# H6 register map
Vendor: Allwinner; Series: H6; File version: 0.1
CPU: CA53 0, little endian, MPU, no FPU, 0 interrupt priority bits
Registers are 32-bit, read-write, reset 0x0 unless marked. A register's access mark holds for its fields unless they carry their own. Offsets are from the block's base; [hi:lo] are bit positions; {n}, {i} and the like mark numbered series; 'fields as' and 'values as' point back to an identical list.

## SMHC0
Base 0x04020000
Same registers: SMHC1 0x04021000
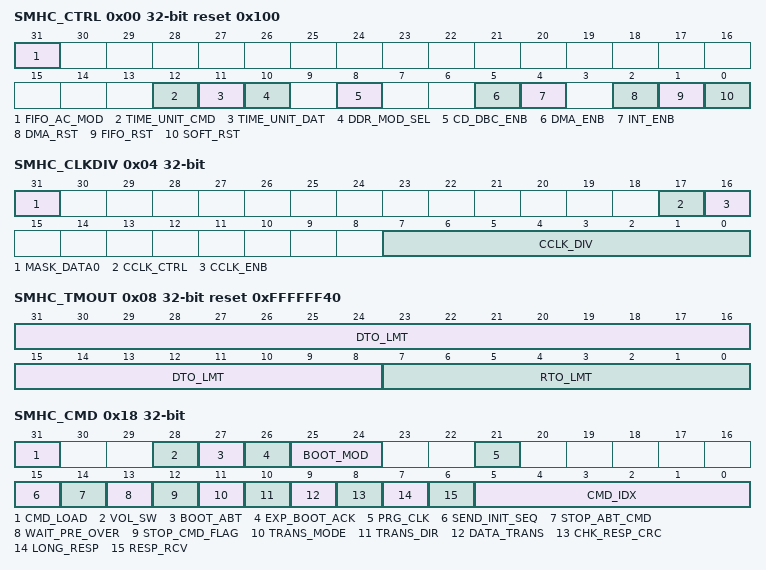
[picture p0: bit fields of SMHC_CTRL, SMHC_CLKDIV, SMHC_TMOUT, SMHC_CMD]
0x00 SMHC_CTRL reset 0x100 — Control Register
  [31] FIFO_AC_MOD — FIFO Access Mode 1: AHB bus 0: DMA bus
    1=AHB (AHB bus); 0=DMA (DMA bus)
  [12] TIME_UNIT_CMD — Time unit for command line Time unit used to calculate command line time out value defined in RTO_LMT. 0: 1 card clock period 1: 256 card clock period
    0=1 card clock period; 1=256 card clock period
  [11] TIME_UNIT_DAT — Time unit for data line Time unit used to calculate data line time out value defined in DTO_LMT. 0: 1 card clock period 1: 256 card clock period
    0=1 card clock period; 1=256 card clock period
  [10] DDR_MOD_SEL — DDR Mode Select Although eMMC`s HS400 speed mode is 8-bit DDR, this filed should be cleared when HS400_MD_EN is set. 0: SDR mode 1: DDR mode
    0=SDR_mode; 1=DDR_mode
  [8] CD_DBC_ENB — Card Detect (Data[3] status) De-bounce Enable 0: Disable de-bounce 1: Enable de-bounce
    0=Disable de-bounce; 1=Enable de-bounce
  [5] DMA_ENB — DMA Global Enable 0: Disable DMA to transfer data, using AHB bus 1: Enable DMA to transfer data
    0=Disable DMA to transfer data, using AHB bus; 1=Enable DMA to transfer data
  [4] INT_ENB — Global Interrupt Enable 0: Disable interrupts 1: Enable interrupts
    0=Disable interrupts; 1=Enable interrupts
  [2] DMA_RST — DMA Reset
  [1] FIFO_RST — FIFO Reset 0: No change 1: Reset FIFO This bit is auto-cleared after completion of reset operation.
    0=No_change; 1=Reset FIFO This bit is auto-cleared after completion of reset operation
  [0] SOFT_RST — Software Reset 0: No change 1: Reset SD/MMC controller This bit is auto-cleared after completion of reset operation.
    0=No_change; 1=Reset SD/MMC controller This bit is auto-cleared after completion of reset operation
0x04 SMHC_CLKDIV — Clock Control Register
  [31] MASK_DATA0 — 0: Do not mask data0 when update clock 1: Mask data0 when update clock
    0=Do not mask data0 when update clock; 1=Mask data0 when update clock
  [17] CCLK_CTRL — Card Clock Output Control 0 : Card clock always on 1 : Turn off card clock when FSM in IDLE state
  [16] CCLK_ENB — Card Clock Enable 0: Card Clock off 1: Card Clock on
    0=Card_Clock_off; 1=Card_Clock_on
  [7:0] CCLK_DIV — Card clock divider n: Source clock is divided by 2*n.(n=0~255) when HS400_MD_EN is set, this field must be cleared.
0x08 SMHC_TMOUT reset 0xFFFFFF40 — Time Out Register
  [31:8] DTO_LMT — Data Timeout Limit
  [7:0] RTO_LMT — Response Timeout Limit
0x0C SMHC_CTYPE — Bus Width Register
  [1:0] CARD_WID — Card Width 00: 1-bit width 01: 4-bit width 1x: 8-bit width
    0=1-bit width; 1=4-bit width; 2=8-bit width
0x10 SMHC_BLKSIZ reset 0x200 — Block Size Register
  [15:0] BLK_SZ — Block Size
0x14 SMHC_BYTCNT reset 0x200 — Byte Count Register
  [31:0] BYTE_CNT — Byte counter Number of bytes to be transferred; should be integer multiple of Block Size for block transfers.
0x18 SMHC_CMD — Command Register
  [31] CMD_LOAD — Start Command. This bit is auto cleared when current command is sent. If there is no any response error happened, a command complete interrupt bit (CMD_OVER) will be set in interrupt register. You should not write any other command before this bit is cleared, or a command busy interrupt bit (CMD_BUSY) will be set in interrupt register.
  [28] VOL_SW — Voltage Switch 0: normal command 1: Voltage switch command, set for CMD11 only
    0=normal command; 1=Voltage switch command, set for CMD11 only
  [27] BOOT_ABT — Boot Abort Setting this bit will terminate the boot operation.
  [26] EXP_BOOT_ACK — Expect Boot Acknowledge. When Software sets this bit along in mandatory boot operation, controller expects a boot acknowledge start pattern of 0-1-0 from the selected card.
  [25:24] BOOT_MOD — Boot Mode 00: Normal command 01: Mandatory Boot operation 10: Alternate Boot operation 11: Reserved
    0=Normal command; 1=Mandatory Boot operation; 2=Alternate Boot operation
  [21] PRG_CLK — Change Clock 0: Normal command 1: Change Card Clock; when this bit is set, controller will change clock domain and clock output. No command will be sent.
    0=Normal command; 1=Change Card Clock; when this bit is set, controller will change clock domain and clock output. No command will be sent.
  [15] SEND_INIT_SEQ — Send Initialization 0: Normal command sending 1: Send initialization sequence before sending this command.
    0=Normal command sending; 1=Send initialization sequence before sending this command
  [14] STOP_ABT_CMD — Stop Abort Command 0: Normal command sending 1: Send Stop or abort command to stop current data transfer in progress.(CMD12, CMD52 for writing `I/O Abort` in SDIO CCCR)
    0=Normal command sending; 1=Send Stop or abort command to stop current data transfer in progress.(CMD12, CMD52 for writing `I/O Abort` in SDIO CCCR)
  [13] WAIT_PRE_OVER — Wait Data Transfer Over 0: Send command at once, do not care of data transferring 1: Wait for data transfer completion before sending current command
    0=Send command at once, do not care of data transferring; 1=Wait for data transfer completion before sending current command
  [12] STOP_CMD_FLAG — Send Stop CMD Automatically (CMD12) 0: Do not send stop command at end of data transfer 1: Send stop command automatically at end of data transfer
    0=Do not send stop command at end of data transfer; 1=Send stop command automatically at end of data transfer
  [11] TRANS_MODE — Transfer Mode 0: Block data transfer command 1: Stream data transfer command
    0=Block data transfer command; 1=Stream data transfer command
  [10] TRANS_DIR — Transfer Direction 0: Read operation 1: Write operation
    0=Read operation; 1=Write operation
  [9] DATA_TRANS — Data Transfer 0: without data transfer 1: with data transfer
    0=without data transfer; 1=with data transfer
  [8] CHK_RESP_CRC — Check Response CRC 0: Do not check response CRC 1: Check response CRC
    0=Do not check response CRC; 1=Check response CRC
  [7] LONG_RESP — Response Type 0:Short Response (48 bits) 1:Long Response (136 bits)
  [6] RESP_RCV — Response Receive 0: Command without Response 1: Command with Response
    0=Command_without_Response; 1=Command_with_Response
  [5:0] CMD_IDX — CMD Index Command index value
0x1C SMHC_CMDARG — Command Argument Register
  [31:0] CMD_ARG — Command argument
0x20 SMHC_RESP0 — Response 0 Register
  [31:0] CMD_RESP0 ro — Response 0 Bit[31:0] of response
0x24 SMHC_RESP1 — Response 1 Register
  [31:0] CMD_RESP1 ro — Response 1 Bit[63:31] of response
0x28 SMHC_RESP2 — Response 2 Register
  [31:0] CMD_RESP2 ro — Response 2 Bit[95:64] of response
0x2C SMHC_RESP3 — Response 3 Register
  [31:0] CMD_RESP3 ro — Response 3 Bit[127:96] of response
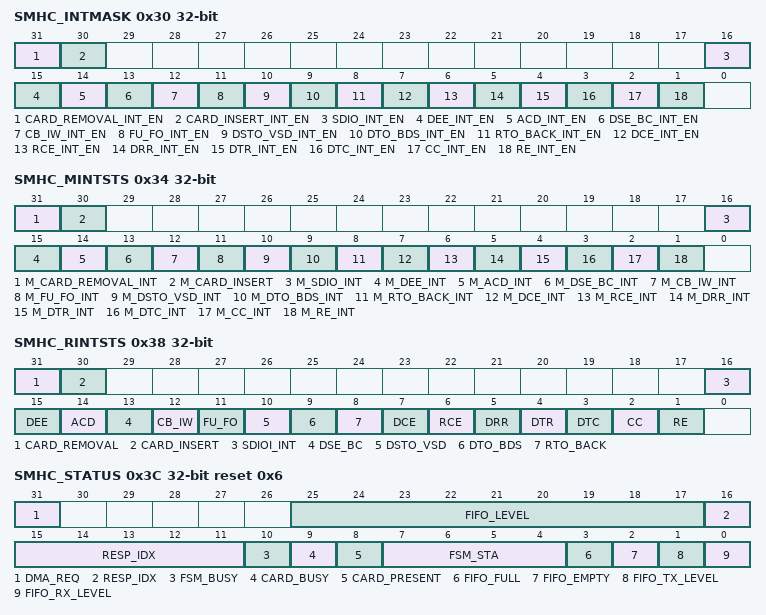
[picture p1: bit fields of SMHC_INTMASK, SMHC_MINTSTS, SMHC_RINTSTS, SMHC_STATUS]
0x30 SMHC_INTMASK — Interrupt Mask Register
  [31] CARD_REMOVAL_INT_EN — Card Removed Interrupt Enable
  [30] CARD_INSERT_INT_EN — Card Inserted Interrupt Enable
  [16] SDIO_INT_EN — SDIO Interrupt Enable
  [15] DEE_INT_EN — Data End-bit Error Interrupt Enable
  [14] ACD_INT_EN — Auto Command Done Interrupt Enable
  [13] DSE_BC_INT_EN — Data Start Error Interrupt Enable
  [12] CB_IW_INT_EN — Command Busy and Illegal Write Interrupt Enable
  [11] FU_FO_INT_EN — FIFO Underrun/Overflow Interrupt Enable
  [10] DSTO_VSD_INT_EN — Data Starvation Timeout/V1.8 Switch Done Interrupt Enable
  [9] DTO_BDS_INT_EN — Data Timeout/Boot Data Start Interrupt Enable
  [8] RTO_BACK_INT_EN — Response Timeout/Boot ACK Received Interrupt Enable
  [7] DCE_INT_EN — Data CRC Error Interrupt Enable
  [6] RCE_INT_EN — Response CRC Error Interrupt Enable
  [5] DRR_INT_EN — Data Receive Request Interrupt Enable
  [4] DTR_INT_EN — Data Transmit Request Interrupt Enable
  [3] DTC_INT_EN — Data Transfer Complete Interrupt Enable
  [2] CC_INT_EN — Command Complete Interrupt Enable
  [1] RE_INT_EN — Response Error Interrupt Enable
0x34 SMHC_MINTSTS — Masked interrupt Status Register
  [31] M_CARD_REMOVAL_INT — Card Removed
  [30] M_CARD_INSERT — Card Inserted
  [16] M_SDIO_INT — SDIO Interrupt
  [15] M_DEE_INT — Data End-bit Error When set during receiving data, it means that host controller does not receive valid data end bit. When set during transmitting data, it means that host controller does not receive CRC status taken or received CRC status taken is negative.
  [14] M_ACD_INT — Auto Command Done When set, it means auto stop command(CMD12) completed.
  [13] M_DSE_BC_INT — Data Start Error When set during receiving data, it means that host controller found a error start bit. When set during transmitting data, it means that busy signal is cleared.
  [12] M_CB_IW_INT — Command Busy and Illegal Write
  [11] M_FU_FO_INT — FIFO Underrun/Overflow
  [10] M_DSTO_VSD_INT — Data Starvation Timeout/V1.8 Switch Done
  [9] M_DTO_BDS_INT — Data Timeout/Boot Data Start
  [8] M_RTO_BACK_INT — Response Timeout/Boot ACK Received
  [7] M_DCE_INT — Data CRC Error When set during receiving data, it means that the received data have data CRC error. When set during transmitting data, it means that the received CRC status taken is negative.
  [6] M_RCE_INT — Response CRC Error
  [5] M_DRR_INT — Data Receive Request When set, it means that there are enough data in FIFO during receiving data.
  [4] M_DTR_INT — Data Transmit Request When set, it means that there are enough space in FIFO during transmitting data.
  [3] M_DTC_INT — Data Transfer Complete
  [2] M_CC_INT — Command Complete
  [1] M_RE_INT — Response Error When set, Transmit Bit error or End Bit error or CMD Index error may occurs.
0x38 SMHC_RINTSTS — Raw Interrupt Status Register
  [31] CARD_REMOVAL write-1-clears — Card Removed This is write-1-to-clear bits.
  [30] CARD_INSERT write-1-clears — Card Inserted This is write-1-to-clear bits.
  [16] SDIOI_INT write-1-clears — SDIO Interrupt This is write-1-to-clear bits.
  [15] DEE write-1-clears — Data End-bit Error When set during receiving data, it means that host controller does not receive valid data end bit. When set during transmitting data, it means that host controller does not receive CRC status taken. This is write-1-to-clear bits.
  [14] ACD write-1-clears — Auto Command Done When set, it means auto stop command(CMD12) completed. This is write-1-to-clear bits.
  [13] DSE_BC write-1-clears — Data Start Error When set during receiving data, it means that host controller found a error start bit. When set during transmitting data, it means that busy signal is cleared. This is write-1-to-clear bits.
  [12] CB_IW write-1-clears — Command Busy and Illegal Write This is write-1-to-clear bits.
  [11] FU_FO write-1-clears — FIFO Underrun/Overflow This is write-1-to-clear bits.
  [10] DSTO_VSD write-1-clears — Data Starvation Timeout/V1.8 Switch Done This is write-1-to-clear bits.
  [9] DTO_BDS write-1-clears — Data Timeout/Boot Data Start This is write-1-to-clear bits.
  [8] RTO_BACK write-1-clears — Response Timeout/Boot ACK Received This is write-1-to-clear bits.
  [7] DCE write-1-clears — Data CRC Error When set during receiving data, it means that the received data have data CRC error. When set during transmitting data, it means that the received CRC status taken is negative. This is write-1-to-clear bits.
  [6] RCE write-1-clears — Response CRC Error This is write-1-to-clear bits.
  [5] DRR write-1-clears — Data Receive Request When set, it means that there are enough data in FIFO during receiving data. This is write-1-to-clear bits.
  [4] DTR write-1-clears — Data Transmit Request When set, it means that there are enough space in FIFO during transmitting data. This is write-1-to-clear bits.
  [3] DTC write-1-clears — Data Transfer Complete This is write-1-to-clear bits.
  [2] CC write-1-clears — Command Complete This is write-1-to-clear bits.
  [1] RE write-1-clears — Response Error When set, Transmit Bit error or End Bit error or CMD Index error may occurs. This is write-1-to-clear bits.
0x3C SMHC_STATUS reset 0x6 — Status Register
  [31] DMA_REQ ro — DMA Request DMA request signal state
  [25:17] FIFO_LEVEL ro — FIFO Level Number of filled locations in FIFO
  [16:11] RESP_IDX ro — Response Index Index of previous response, including any auto-stop sent by controller
  [10] FSM_BUSY ro — Data FSM Busy Data transmit or receive state-machine is busy
  [9] CARD_BUSY ro — Card data busy Inverted version of DATA[0] 0: card data not busy 1: card data busy
    0=card_data_not_busy; 1=card_data_busy
  [8] CARD_PRESENT ro — Data[3] status level of DATA[3], checks whether card is present 0: card not present 1: card present
    0=card_not_present; 1=card_present
  [7:4] FSM_STA ro — Command FSM States 0000: Idle 0001: Send init sequence 0010: TX CMD start bit 0011: TX CMD TX bit 0100: TX CMD index + argument 0101: TX CMD CRC7 0110: TX CMD end bit 0111: RX response start bit 1000: RX response IRQ response 1001: RX response TX bit 1010: RX response CMD index 1011: RX response data 1100: RX response CRC7 1101: RX response end bit 1110: CMD path wait NCC 1111: Wait; CMD-to-response turnaround
  [3] FIFO_FULL ro — FIFO Full 1: FIFO full 0: FIFO not full
    1=FIFO_full; 0=FIFO (FIFO not full)
  [2] FIFO_EMPTY ro — FIFO Empty 1: FIFO Empty 0: FIFO not Empty
    1=FIFO_Empty; 0=FIFO_not_Empty
  [1] FIFO_TX_LEVEL ro — FIFO TX Water Level Flag 0: FIFO didn`t reach transmit trigger level 1: FIFO reached transmit trigger level
    0=FIFO didn`t reach transmit trigger level; 1=FIFO reached transmit trigger level
  [0] FIFO_RX_LEVEL ro — FIFO TX Water Level Flag 0: FIFO didn`t reach receive trigger level 1: FIFO reached receive trigger level
    0=FIFO didn`t reach receive trigger level; 1=FIFO reached receive trigger level
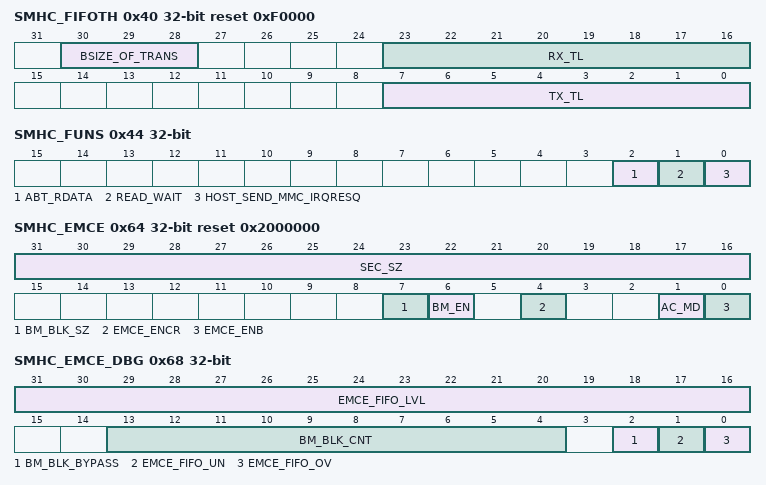
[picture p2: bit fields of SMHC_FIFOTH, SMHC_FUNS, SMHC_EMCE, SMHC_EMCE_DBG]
0x40 SMHC_FIFOTH reset 0xF0000 — FIFO Water Level Register
  [30:28] BSIZE_OF_TRANS — Burst Size of Multiple Transaction 000: 1 transfers 001: 4 010: 8 011: 16 Others: Reserved Should be programmed same as DMA controller multiple transaction size. The units for transfers are the DWORD. A single transfer would be signaled based on this value. Value should be sub-multiple of (RX_TL + 1) and (FIFO_DEPTH - TX_TL) FIFO_DEPTH = 256 FIFO_SIZE = 256 * 32 = 1K Recommended: MSize = 16, TX_TL = 240, RX_TL = 15
    0=1 transfers; 1=_4; 2=_8; 3=16 Others: Reserved Should be programmed same as DMA controller multiple transaction size. The units for transfers are the DWORD. A single transfer would be signaled based on this value. Value should be sub-multiple of (RX_TL + 1) and (FIFO_DEPTH - TX_TL) FIFO_DEPTH = 256 FIFO_SIZE = 256 * 32 = 1K Recommended: MSize = 16, TX_TL = 240, RX_TL = 15
  [23:16] RX_TL — RX Trigger Level 0x0~0xFE: RX Trigger Level is 0~254 0xFF: Reserved FIFO threshold when FIFO request host to receive data from FIFO. When FIFO data level is greater than this value, DMA is request is raised if DMA enabled, or RX interrupt bit is set if interrupt enabled. At the end of packet, if the last transfer is less than this level, the value is ignored and relative request will be raised as usual. Recommended: 15 (means greater than 15)
  [7:0] TX_TL — TX Trigger Level 0x1~0xFF: TX Trigger Level is 1~255 0x0: no trigger FIFO threshold when FIFO requests host to transmit data to FIFO. When FIFO data level is less than or equal to this value, DMA TX request is raised if DMA enabled, or TX request interrupt bit is set if interrupt enabled. At the end of packet, if the last transfer is less than this level, the value is ignored and relative request will be raised as usual. Recommended: 240(means less than or equal to 240)
    0=no trigger FIFO threshold when FIFO requests host to transmit data to FIFO. When FIFO data level is less than or equal to this value, DMA TX request is raised if DMA enabled, or TX request interrupt bit is set if interrupt enabled. At the end of packet, if the last transfer is less than this level, the value is ignored and relative request will be raised as usual. Recommended: 240(means less than or equal to 240)
0x44 SMHC_FUNS — FIFO Function Select Register
  [2] ABT_RDATA — Abort Read Data 0: Ignored 1: After suspend command is issued during read-transfer, software polls card to find when suspend happened. Once suspend occurs, software sets bit to reset data state-machine, which is waiting for next block of data. Used in SDIO card suspends sequence. This bit is auto-cleared once controller reset to idle state.
    0=Ignored; 1=After suspend command is issued during read-transfer, software polls card to find when suspend happened. Once suspend occurs, software sets bit to reset data state-machine, which is waiting for next block of data. Used in SDIO card suspends sequence. This bit is auto-cleared once controller reset to idle state.
  [1] READ_WAIT — Read Wait 0: Clear SDIO read wait 1: Assert SDIO read wait
    0=Clear SDIO read wait; 1=Assert SDIO read wait
  [0] HOST_SEND_MMC_IRQRESQ — Host Send MMC IRQ Response 0: Ignored 1: Send auto IRQ response When host is waiting MMC card interrupt response, setting this bit will make controller cancel wait state and return to idle state, at which time, controller will receive IRQ response sent by itself. This bit is auto-cleared after response is sent.
    0=Ignored; 1=Send auto IRQ response When host is waiting MMC card interrupt response, setting this bit will make controller cancel wait state and return to idle state, at which time, controller will receive IRQ response sent by itself. This bit is auto-cleared after response is sent.
0x48 SMHC_TBC0
  [31:0] TBC0 ro — Transferred Count 0 Number of bytes transferred between card and internal FIFO. The register should be accessed in full to avoid read-coherency problems and read only after data transfer completes.
0x4C SMHC_TBC1
  [31:0] TBC1 ro — Transferred Count 1 Number of bytes transferred between Host/DMA memory and internal FIFO. The register should be accessed in full to avoid read-coherency problems and read only after data transfer completes.
0x54 SMHC_CSDC reset 0x3 — CRC Status Detect Control Register
  [3:0] CRC_DET_PARA — 110: HS400 speed mode 011: Other speed mode
0x64 SMHC_EMCE reset 0x2000000 — Embedded Encrypt and Decrypt Control Register
  [31:16] SEC_SZ — Sector Size of EMCE.
  [7] BM_BLK_SZ — The size of bitmap-block size. 0: 512 Byte 1: 4096 Byte
    0=512 Byte; 1=4096 Byte
  [6] BM_EN — 0: Disable bitmap. 1: Enable bitmap. This bit is valid when EMCE is enable and use DMA transfer. If this bit is cleared, all data blocks associated with one write/read command will be encrypted/decrypted. If this bit is set, the data will be divided into many bitmap-blocks aligned to BM_BLK_SZ. The bitmap-blocks are associated with the bits of SMHC_EMCE_BMn register, and will be or will not be encrypted/decrypted determined by these bitmap bits. SMHC can support the last bitmap-block is not aligned to BM_BLK_SZ.
    0=Disable bitmap; 1=Enable bitmap. This bit is valid when EMCE is enable and use DMA transfer. If this bit is cleared, all data blocks associated with one write/read command will be encrypted/decrypted. If this bit is set, the data will be divided into many bitmap-blocks aligned to BM_BLK_SZ. The bitmap-blocks are associated with the bits of SMHC_EMCE_BMn register, and will be or will not be encrypted/decrypted determined by these bitmap bits. SMHC can support the last bitmap-block is not aligned to BM_BLK_SZ.
  [4] EMCE_ENCR — 0:disabled encrypt and decrypt.Encrypt and decrypt will be bypassed in EMCE 1:enable encrypt and decrypt This bit is only available when EMCE_ENB is 1.
  [1] AC_MD — Access Mode 0: Sector mode. The data address to access device is in sector(512 bytes) units. SMHC_CMDARG is a 32bit sector(512 bytes) address. 1: Byte mode. The data address to access device is in bytes units. SMHC_CMDARG is a 32bit byte address.
    0=Sector mode. The data address to access device is in sector(512 bytes) units. SMHC_CMDARG is a 32bit sector(512 bytes) address.; 1=Byte mode. The data address to access device is in bytes units. SMHC_CMDARG is a 32bit byte address.
  [0] EMCE_ENB — EMCE Enable 0: EMCE is disabled.EMCE will be bypass by host controller. 1: EMCE is enabled. The data of current command shall go through EMCE.Encrypt or decrypt is decided by EMCE_ENCR. The type and configuration of encryption algorithm are determined by EMCE`s initial process, and out of this specification.
    0=disabled_point_EMCE (EMCE is disabled.EMCE will be bypass by host controller.); 1=enabled (EMCE is enabled. The data of current command shall go through EMCE.Encrypt or decrypt is decided by EMCE_ENCR. The type and configuration of encryption algorithm are determined by EMCE`s initial process, and out of this specification.)
0x68 SMHC_EMCE_DBG — Embedded Encrypt and Decrypt Debug Register
  [31:16] EMCE_FIFO_LVL ro — EMCE FIFO level in byte When transmitting data, it shows the number of data in FIFO which received from EMCE , then send from SMHC to device. When receiving dat, it shows the number of data in FIFO which is read from device, then send to EMCE.
  [13:4] BM_BLK_CNT ro — Bitmap-block couter This field counts the number of bitmap-block for each write/read command. It is cleared when lunch a new command.
  [2] BM_BLK_BYPASS ro — 1: Current bitmap-block is bypassed, and will not be encrypted/decrypted. 0: Current will be encrypted/decrypted. This bit is valid only when EMCE_ENB is 1 and EMCE_ENCR is 0.
    1=Current_bitmap_minus_block (Current bitmap-block is bypassed, and will not be encrypted/decrypted.); 0=Current will be encrypted/decrypted. This bit is valid only when EMCE_ENB is 1 and EMCE_ENCR is 0.
  [1] EMCE_FIFO_UN ro — When this bit is set, EMCE FIFO is underrun.
  [0] EMCE_FIFO_OV ro — When this bit is set, EMCE FIFO is overflow.
0x78 SMHC_HWRST reset 0x1 — Hardware Reset Register
  [0] HW_RST — 1: Active mode 0: Reset These bits cause the cards to enter pre-idle state, which requires them to be re-initialized.
    1=Active_mode; 0=Reset These bits cause the cards to enter pre-idle state, which requires them to be re-initialized
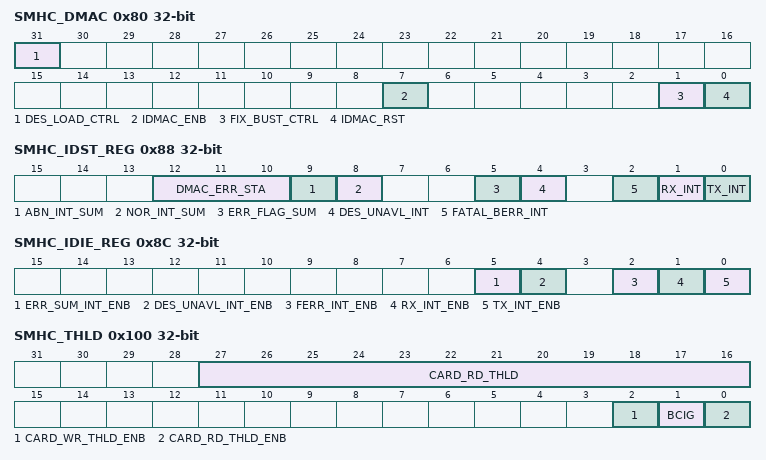
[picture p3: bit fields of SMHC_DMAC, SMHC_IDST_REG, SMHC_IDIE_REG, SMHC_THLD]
0x80 SMHC_DMAC — DMA Control Register
  [31] DES_LOAD_CTRL wo — When DMAC fetches a descriptor, if the valid bit of a descriptor is not set, DMAC FSM will go to the suspend state. Setting this bit will make DMAC re-fetch descriptor again and do the transfer normally.
  [7] IDMAC_ENB — IDMAC Enable. When set, the IDMAC is enabled. DE is read/write.
  [1] FIX_BUST_CTRL — Fixed Burst. Controls whether the AHB Master interface performs fixed burst transfers or not. When set, the AHB will use only SINGLE, INCR4, INCR8 during start of normal burst transfers. When reset, the AHB will use SINGLE and INCR burst transfer operations.
  [0] IDMAC_RST — DMA Reset. When set, the DMA Controller resets all its internal registers. SWR is read/write. It is automatically cleared after 1 clock cycle.
0x84 SMHC_DLBA_REG
  [31:0] DES_BASE_ADDR — Start of Descriptor List. Contains the base address of the First Descriptor. The LSB bits [1:0] are ignored and taken as all-zero by the IDMAC internally. Hence these LSB bits are read-only.
0x88 SMHC_IDST_REG
  [12:10] DMAC_ERR_STA ro — Error Bits. Indicates the type of error that caused a Bus Error. Valid only with Fatal Bus Error bit (IDSTS[2]) set. This field does not generate an interrupt. 001: Host Abort received during transmission 010: Host Abort received during reception Others: Reserved EB is read-only.
    1=Host_Abort_received_during_transmission; 2=Host Abort received during reception
  [9] ABN_INT_SUM write-1-clears — Abnormal Interrupt Summary. Logical OR of the following: IDSTS[2]: Fatal Bus Interrupt IDSTS[4]: Descriptor Unavailable bit Interrupt IDSTS[5]: Card Error Summary Interrupt Only unmasked bits affect this bit. This is a sticky bit and must be cleared each time a corresponding bit that causes AIS to be set is cleared. Writing a 1 clears this bit.
  [8] NOR_INT_SUM write-1-clears — Normal Interrupt Summary. Logical OR of the following: IDSTS[0]: Transmit Interrupt IDSTS[1]: Receive Interrupt Only unmasked bits affect this bit. This is a sticky bit and must be cleared each time a corresponding bit that causes NIS to be set is cleared. Writing a 1 clears this bit.
  [5] ERR_FLAG_SUM write-1-clears — Card Error Summary. Indicates the status of the transaction to/from the card; also present in RINTSTS. Indicates the logical OR of the following bits: EBE: End Bit Error RTO: Response Timeout/Boot ACK Timeout RCRC: Response CRC SBE: Start Bit Error DRTO: Data Read Timeout/BDS timeout DCRC: Data CRC for Receive RE: Response Error Writing a 1 clears this bit.
  [4] DES_UNAVL_INT write-1-clears — Descriptor Unavailable Interrupt. This bit is set when the descriptor is unavailable due to OWN bit = 0 (DES0[31] =0). Writing a 1 clears this bit.
  [2] FATAL_BERR_INT write-1-clears — Fatal Bus Error Interrupt. Indicates that a Bus Error occurred (IDSTS[12:10]). When this bit is set, the DMA disables all its bus accesses. Writing a 1 clears this bit.
  [1] RX_INT write-1-clears — Receive Interrupt. Indicates the completion of data reception for a descriptor. Writing a 1 clears this bit.
  [0] TX_INT write-1-clears — Transmit Interrupt. Indicates that data transmission is finished for a descriptor. Writing a `1` clears this bit.
0x8C SMHC_IDIE_REG
  [5] ERR_SUM_INT_ENB — Card Error summary Interrupt Enable. When set, it enables the Card Interrupt summary.
  [4] DES_UNAVL_INT_ENB — Descriptor Unavailable Interrupt. When set along with Abnormal Interrupt Summary Enable, the Descriptor Unavailable interrupt is enabled.
  [2] FERR_INT_ENB — Fatal Bus Error Enable. When set with Abnormal Interrupt Summary Enable, the Fatal Bus Error Interrupt is enabled. When reset, Fatal Bus Error Enable Interrupt is disabled.
  [1] RX_INT_ENB — Receive Interrupt Enable. When set with Normal Interrupt Summary Enable, Receive Interrupt is enabled. When reset, Receive Interrupt is disabled.
  [0] TX_INT_ENB — Transmit Interrupt Enable. When set with Normal Interrupt Summary Enable, Transmit Interrupt is enabled. When reset, Transmit Interrupt is disabled.
0x100 SMHC_THLD — Card Threshold Control Register
  [27:16] CARD_RD_THLD — Card Read Threshold Size
  [2] CARD_WR_THLD_ENB — (only for SMHC2) Card Write Threshold Enable(HS400) 0: Card write threshold disable 1: Card write threshold enabled Host controller initiates write transfer only if card threshold amount of data is available in transmit FIFO
    0=Card_write_threshold_disable; 1=Card write threshold enabled Host controller initiates write transfer only if card threshold amount of data is available in transmit FIFO
  [1] BCIG — (only for SMHC2) Busy Clear Interrupt Generation 0: Busy Clear Interrupt disabled 1: Busy Clear Interrupt Enabled The application can disable this feature if it does not want to wait for a Busy Clear Interrupt.
    0=Busy_Clear_Interrupt_disabled; 1=Busy Clear Interrupt Enabled The application can disable this feature if it does not want to wait for a Busy Clear Interrupt
  [0] CARD_RD_THLD_ENB — Card Read Threshold Enable 0: Card Read Threshold Disable 1: Card Read Threshold Enable Host controller initiates Read Transfer only if CARD_RD_THLD amount of space is available in receive FIFO.
    0=Card_Read_Threshold_Disable; 1=Card Read Threshold Enable Host controller initiates Read Transfer only if CARD_RD_THLD amount of space is available in receive FIFO
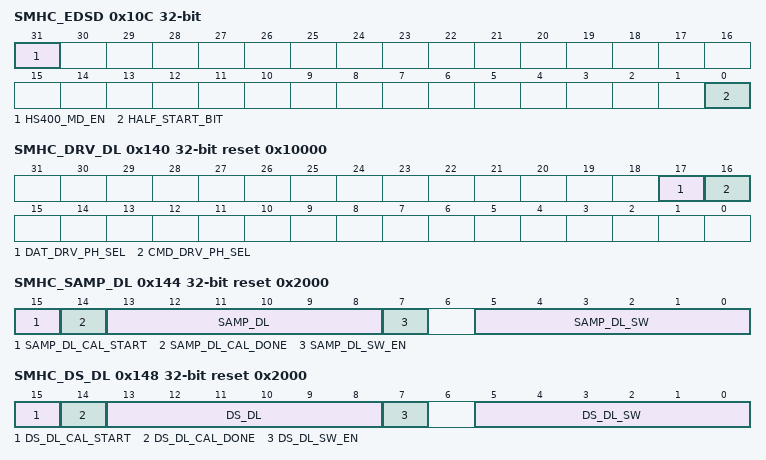
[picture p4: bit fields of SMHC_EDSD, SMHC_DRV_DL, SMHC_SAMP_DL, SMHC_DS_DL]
0x10C SMHC_EDSD — eMMC4.5 DDR Start Bit Detection Control Register
  [31] HS400_MD_EN — HS400_MD_EN(for SMHC2 only) HS400 Mode Enable 0: Disable 1: Enable It is required to set this bit to '1' before initiating any data transfer CMD in HS400 mode.
    0=Disable; 1=Enable It is required to set this bit to '1' before initiating any data transfer CMD in HS400 mode
  [0] HALF_START_BIT — Control for start bit detection mechanism inside mstorage based on duration of start bit. For eMMC 4.5, start bit can be: 0: Full cycle 1: Less than one full cycle Set HALF_START_BIT=1 for eMMC 4.5 and above; set to 0 for SD applications.
    0=Full_cycle; 1=Less than one full cycle Set HALF_START_BIT=1 for eMMC 4.5 and above; set to 0 for SD applications
0x110 SMHC_RESP_CRC
  [6:0] RESP_CRC ro — Response CRC Response CRC from device.
0x114 SMHC_DAT7_CRC
  [31:0] DAT7_CRC ro — Data[7] CRC CRC in data[7] from device. In 8bit DDR mode, the higher 16 bits indicate the CRC of even data, and the lower 16 bits indicate the CRC of odd data. In 4 bit DDR mode,it is not used. In SDR mode, the higher 16 bits indicate the CRC of all data.
0x118 SMHC_DAT6_CRC
  [31:0] DAT6_CRC ro — Data[6] CRC CRC in data[6] from device. In 8bit DDR mode, the higher 16 bits indicate the CRC of even data, and the lower 16 bits indicate the CRC of odd data. In 4 bit DDR mode,it is not used. In SDR mode, the higher 16 bits indicate the CRC of all data.
0x11C SMHC_DAT5_CRC
  [31:0] DAT5_CRC ro — Data[5] CRC CRC in data[5] from device. In 8bit DDR mode, the higher 16 bits indicate the CRC of even data, and the lower 16 bits indicate the CRC of odd data. In 4 bit DDR mode,it is not used. In SDR mode, the higher 16 bits indicate the CRC of all data.
0x120 SMHC_DAT4_CRC
  [31:0] DAT4_CRC ro — Data[4] CRC CRC in data[4] from device. In 8 bit DDR mode, the higher 16 bits indicate the CRC of even data, and the lower 16 bits indicate the CRC of odd data. In 4 bit DDR mode, the higher 16 bits indicate the CRC of odd data, and the lower 16 bits indicate the CRC of even data. In SDR mode, the higher 16 bits indicate the CRC of all data.
0x124 SMHC_DAT3_CRC
  [31:0] DAT3_CRC ro — Data[3] CRC CRC in data[3] from device. In 8 bit DDR mode, the higher 16 bits indicate the CRC of even data, and the lower 16 bits indicate the CRC of odd data. In 4 bit DDR mode, the higher 16 bits indicate the CRC of odd data, and the lower 16 bits indicate the CRC of even data. In SDR mode, the higher 16 bits indicate the CRC of all data.
0x128 SMHC_DAT2_CRC
  [31:0] DAT2_CRC ro — Data[2] CRC CRC in data[2] from device. In 8 bit DDR mode, the higher 16 bits indicate the CRC of even data, and the lower 16 bits indicate the CRC of odd data. In 4 bit DDR mode, the higher 16 bits indicate the CRC of odd data, and the lower 16 bits indicate the CRC of even data. In SDR mode, the higher 16 bits indicate the CRC of all data.
0x12C SMHC_DAT1_CRC
  [31:0] DAT1_CRC ro — Data[1] CRC CRC in data[1] from device. In 8 bit DDR mode, the higher 16 bits indicate the CRC of even data, and the lower 16 bits indicate the CRC of odd data. In 4 bit DDR mode, the higher 16 bits indicate the CRC of odd data, and the lower 16 bits indicate the CRC of even data. In SDR mode, the higher 16 bits indicate the CRC of all data.
0x130 SMHC_DAT0_CRC
  [31:0] DAT0_CRC ro — Data[0] CRC CRC in data[0] from device. In 8 bit DDR mode, the higher 16 bits indicate the CRC of even data, and the lower 16 bits indicate the CRC of odd data. In 4 bit DDR mode, the higher 16 bits indicate the CRC of odd data, and the lower 16 bits indicate the CRC of even data. In SDR mode, the higher 16 bits indicate the CRC of all data.
0x134 SMHC_CRC_STA — CRC Status from Device in Write Operation
  [2:0] CRC_STA ro — CRC Status CRC status from device in write operation Positive CRC status token: 3`b010 Negative CRC status token: 3`b101
0x140 SMHC_DRV_DL reset 0x10000 — Drive Delay Control Register
  [17] DAT_DRV_PH_SEL — Data Drive Phase Select 0: Data drive phase offset is 90 at SDR mode, 45 at DDR mode, 90 at HS400 mode. 1: Data drive phase offset is 180 at SDR mode, 90 at DDR mode, 0 at HS400 mode.
    0=Data drive phase offset is 90 at SDR mode, 45 at DDR mode, 90 at HS400 mode; 1=Data drive phase offset is 180 at SDR mode, 90 at DDR mode, 0 at HS400 mode
  [16] CMD_DRV_PH_SEL — Command Drive Phase Select 0: Command drive phase offset is 90 at SDR mode, 45 at DDR mode, 90 at HS400 mode. 1: Command drive phase offset is 180 at SDR mode, 90 at DDR mode, 0 at HS400 mode.
    0=Command drive phase offset is 90 at SDR mode, 45 at DDR mode, 90 at HS400 mode; 1=Command drive phase offset is 180 at SDR mode, 90 at DDR mode, 0 at HS400 mode
0x144 SMHC_SAMP_DL reset 0x2000
  [15] SAMP_DL_CAL_START — Sample Delay Calibration Start When set, start sample delay chain calibration.
  [14] SAMP_DL_CAL_DONE ro — Sample Delay Calibration Done When set, it means that sample delay chain calibration is done and the result of calibration is shown in SAMP_DL.
  [13:8] SAMP_DL ro — Sample Delay It indicates the number of delay cells corresponding to current card clock. The delay time generated by these delay cells is equal to the cycle of card clock nearly. Generally, it is necessary to do drive delay calibration when card clock is changed. This bit is valid only when SAMP_DL_CAL_DONE is set.
  [7] SAMP_DL_SW_EN — Sample Delay Software Enable When set, enable sample delay specified at SAMP_DL_SW
  [5:0] SAMP_DL_SW — Sample Delay Software The relative delay between clock line and command line, data lines. It can be determined according to the value of SAMP_DL, the cycle of card clock and device`s input timing requirement.
0x148 SMHC_DS_DL reset 0x2000 — Data Strobe Delay Control Register
  [15] DS_DL_CAL_START — Data Strobe Delay Calibration Start When set, start sample delay chain calibration.
  [14] DS_DL_CAL_DONE ro — Data Strobe Delay Calibration Done When set, it means that sample delay chain calibration is done and the result of calibration is shown in DS_DL.
  [13:8] DS_DL ro — Data Strobe Delay It indicates the number of delay cells corresponding to current card clock. The delay time generated by these delay cells is equal to the cycle of SMHC`s clock nearly. This bit is valid only when SAMP_DL_CAL_DONE is set.
  [7] DS_DL_SW_EN — Sample Delay Software Enable
  [5:0] DS_DL_SW — Data Strobe Delay Software
{0x150+4i} SMHC_EMCE_BMn[{i}] (i=0..31) — SMHC_EMCE_BMn[{i}]
  [31:0] BM — From LSB to MSB of SMHC_EMCE_BMn, each bit associates with one bitmap-block. 0: The associated bitmap-block will be bypassed in EMCE. 1: The associated bitmap-block will be encrypted/decrypted in EMCE. The total bits of all bitmap registers are 32*32=1024. The size of bitmap-block is determined by SMHC_EMCE BM_BLK_SZ, it may be 512 Byte or 4096 Byte. The maximum data size indicated by all 32 bitmap registers is 512K Byte or 4M Byte. In other words, the maximum data size of one multi-block write/read command is limited to 512K Byte or 4M Byte.
0x200 SMHC_FIFO — Read/ Write FIFO
  [31:0] TX/RX_FIFO — Data FIFO

## SMHC2
Base 0x04022000
Registers as SMHC0; these are added or differ:
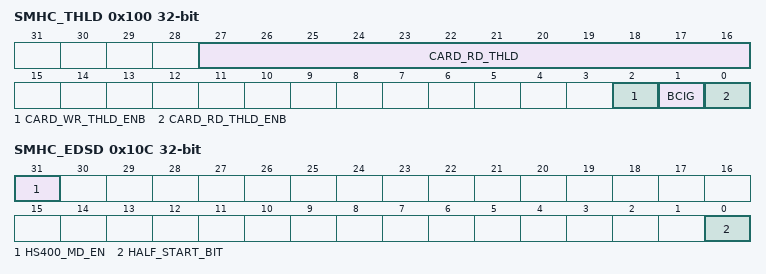
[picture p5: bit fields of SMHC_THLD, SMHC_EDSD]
0x100 SMHC_THLD — Card Threshold Control Register
  fields as SMHC0.SMHC_THLD
0x10C SMHC_EDSD — eMMC4.5 DDR Start Bit Detection Control Register
  fields as SMHC0.SMHC_EDSD
